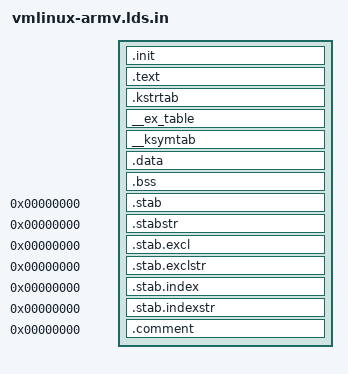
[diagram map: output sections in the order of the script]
/* ld script to make ARM Linux kernel
 * taken from the i386 version by Russell King
 * Written by Martin Mares <mj@atrey.karlin.mff.cuni.cz>
 */
OUTPUT_ARCH(arm)
ENTRY(stext)
SECTIONS
{
	. = TEXTADDR;
	.init : {			/* Init code and data		*/
		_stext = .;
		__init_begin = .;
			*(.text.init .text.init.*)
		__proc_info_begin = .;
			KEEP(*(.proc.info))
		__proc_info_end = .;
		__arch_info_begin = .;
			KEEP(*(.arch.info))
		__arch_info_end = .;
		__tagtable_begin = .;
			KEEP(*(.taglist))
		__tagtable_end = .;
			*(.data.init .data.init.*)
		. = ALIGN(16);
		__setup_start = .;
			KEEP(*(.setup.init))
		__setup_end = .;
		__initcall_start = .;
			KEEP(*(.initcall.init))
		__initcall_end = .;
		. = ALIGN(4096);
		__init_end = .;
	}

	/DISCARD/ : {			/* Exit code and data		*/
		*(.text.exit)
		*(.data.exit)
		*(.exitcall.exit)
	}

	.text : {			/* Real text segment		*/
		_text = .;		/* Text and read-only data	*/
			*(.text .text.*)
			*(.fixup)
			*(.gnu.warning)
			*(.rodata)
			*(.rodata.*)
			*(.glue_7)
			*(.glue_7t)
		*(.got)			/* Global offset table		*/

		_etext = .;		/* End of text section		*/
	}

	.kstrtab : { KEEP(*(.kstrtab)) }

	. = ALIGN(16);
	__ex_table : {			/* Exception table		*/
		__start___ex_table = .;
			KEEP(*(__ex_table))
		__stop___ex_table = .;
	}

	__ksymtab : {			/* Kernel symbol table		*/
		__start___ksymtab = .;
			KEEP(*(__ksymtab))
		__stop___ksymtab = .;
	}

	. = ALIGN(8192);

	.data : {
		/*
		 * first, the init task union, aligned
		 * to an 8192 byte boundary.
		 */
		KEEP(*(.init.task))

		/*
		 * then the cacheline aligned data
		 */
		. = ALIGN(32);
		*(.data.cacheline_aligned)

		/*
		 * and the usual data section
		 */
		*(.data .data.*)

		/* Align the initial ramdisk image (INITRD) on page boundaries. */
		. = ALIGN(4096);
		__rd_start = .;
		KEEP(*(.initrd))
		. = ALIGN(4096);
		__rd_end = .;

		/* Align the modules image (MODRD) on page boundaries. */
		. = ALIGN(4096);
		__modrd_start = .;
		KEEP(*(.modrd))
		. = ALIGN(4096);
		__modrd_end = .;

		/* Align the init cramdisk image. */
		. = ALIGN(4096);
		__crd_init_start = .;
		KEEP(*(.cramdisk_init))
		. = ALIGN(4096);
		__crd_init_end = .;
		
		/* Align the cramdisk image. */
		. = ALIGN(4096);
		__crd_start = .;
		KEEP(*(.cramdisk))
		. = ALIGN(4096);
		__crd_end = .;

		CONSTRUCTORS

		_edata = .;
	}

	.bss : {
		__bss_start = .;	/* BSS				*/
		*(.bss .bss.*)
		*(COMMON)
		_end = . ;
	}
					/* Stabs debugging sections.	*/
	.stab 0 : { *(.stab) }
	.stabstr 0 : { *(.stabstr) }
	.stab.excl 0 : { *(.stab.excl) }
	.stab.exclstr 0 : { *(.stab.exclstr) }
	.stab.index 0 : { *(.stab.index) }
	.stab.indexstr 0 : { *(.stab.indexstr) }
	.comment 0 : { *(.comment) }
}
